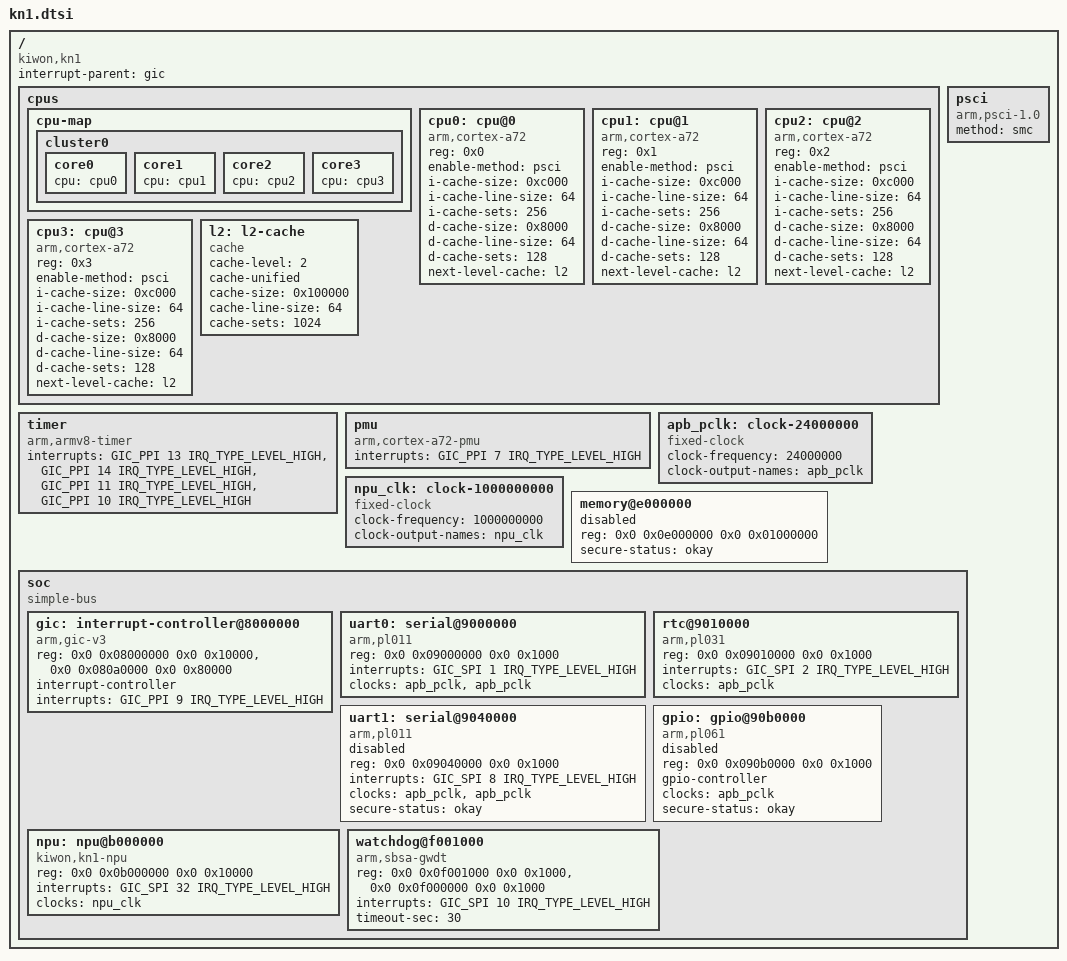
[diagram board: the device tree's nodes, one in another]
// SPDX-License-Identifier: GPL-2.0-or-later OR MIT
// SPDX-FileCopyrightText: 2026 Kiwon Kwon
/*
 * Kiwon kn1 SoC: 4x Cortex-A72, GICv3, PL011 UARTs, PL031 RTC,
 * SBSA generic watchdog, secure PL061 GPIO, secure on-chip RAM and the
 * kn1-npu.
 */

#include <dt-bindings/interrupt-controller/arm-gic.h>
#include <dt-bindings/interrupt-controller/irq.h>

/ {
	compatible = "kiwon,kn1";
	interrupt-parent = <&gic>;
	#address-cells = <2>;
	#size-cells = <2>;

	cpus {
		#address-cells = <1>;
		#size-cells = <0>;

		cpu-map {
			cluster0 {
				core0 {
					cpu = <&cpu0>;
				};
				core1 {
					cpu = <&cpu1>;
				};
				core2 {
					cpu = <&cpu2>;
				};
				core3 {
					cpu = <&cpu3>;
				};
			};
		};

		cpu0: cpu@0 {
			device_type = "cpu";
			compatible = "arm,cortex-a72";
			reg = <0x0>;
			enable-method = "psci";
			i-cache-size = <0xc000>;
			i-cache-line-size = <64>;
			i-cache-sets = <256>;
			d-cache-size = <0x8000>;
			d-cache-line-size = <64>;
			d-cache-sets = <128>;
			next-level-cache = <&l2>;
		};

		cpu1: cpu@1 {
			device_type = "cpu";
			compatible = "arm,cortex-a72";
			reg = <0x1>;
			enable-method = "psci";
			i-cache-size = <0xc000>;
			i-cache-line-size = <64>;
			i-cache-sets = <256>;
			d-cache-size = <0x8000>;
			d-cache-line-size = <64>;
			d-cache-sets = <128>;
			next-level-cache = <&l2>;
		};

		cpu2: cpu@2 {
			device_type = "cpu";
			compatible = "arm,cortex-a72";
			reg = <0x2>;
			enable-method = "psci";
			i-cache-size = <0xc000>;
			i-cache-line-size = <64>;
			i-cache-sets = <256>;
			d-cache-size = <0x8000>;
			d-cache-line-size = <64>;
			d-cache-sets = <128>;
			next-level-cache = <&l2>;
		};

		cpu3: cpu@3 {
			device_type = "cpu";
			compatible = "arm,cortex-a72";
			reg = <0x3>;
			enable-method = "psci";
			i-cache-size = <0xc000>;
			i-cache-line-size = <64>;
			i-cache-sets = <256>;
			d-cache-size = <0x8000>;
			d-cache-line-size = <64>;
			d-cache-sets = <128>;
			next-level-cache = <&l2>;
		};

		l2: l2-cache {
			compatible = "cache";
			cache-level = <2>;
			cache-unified;
			cache-size = <0x100000>;
			cache-line-size = <64>;
			cache-sets = <1024>;
		};
	};

	psci {
		compatible = "arm,psci-1.0";
		method = "smc";
	};

	timer {
		compatible = "arm,armv8-timer";
		interrupts = <GIC_PPI 13 IRQ_TYPE_LEVEL_HIGH>,
			     <GIC_PPI 14 IRQ_TYPE_LEVEL_HIGH>,
			     <GIC_PPI 11 IRQ_TYPE_LEVEL_HIGH>,
			     <GIC_PPI 10 IRQ_TYPE_LEVEL_HIGH>;
		interrupt-names = "sec-phys", "phys", "virt", "hyp-phys";
	};

	pmu {
		compatible = "arm,cortex-a72-pmu";
		interrupts = <GIC_PPI 7 IRQ_TYPE_LEVEL_HIGH>;
	};

	apb_pclk: clock-24000000 {
		compatible = "fixed-clock";
		#clock-cells = <0>;
		clock-frequency = <24000000>;
		clock-output-names = "apb_pclk";
	};

	/* The NPU does not model time; the rate only describes the clock */
	npu_clk: clock-1000000000 {
		compatible = "fixed-clock";
		#clock-cells = <0>;
		clock-frequency = <1000000000>;
		clock-output-names = "npu_clk";
	};

	/* On-chip RAM for the secure world only (TF-A BL2 and BL31) */
	memory@e000000 {
		device_type = "memory";
		reg = <0x0 0x0e000000 0x0 0x01000000>;
		status = "disabled";
		secure-status = "okay";
	};

	soc {
		compatible = "simple-bus";
		#address-cells = <2>;
		#size-cells = <2>;
		ranges;

		gic: interrupt-controller@8000000 {
			compatible = "arm,gic-v3";
			reg = <0x0 0x08000000 0x0 0x10000>,	/* GICD */
			      <0x0 0x080a0000 0x0 0x80000>;	/* GICR x4 */
			#interrupt-cells = <3>;
			interrupt-controller;
			interrupts = <GIC_PPI 9 IRQ_TYPE_LEVEL_HIGH>;
		};

		uart0: serial@9000000 {
			compatible = "arm,pl011", "arm,primecell";
			reg = <0x0 0x09000000 0x0 0x1000>;
			interrupts = <GIC_SPI 1 IRQ_TYPE_LEVEL_HIGH>;
			clocks = <&apb_pclk>, <&apb_pclk>;
			clock-names = "uartclk", "apb_pclk";
		};

		rtc@9010000 {
			compatible = "arm,pl031", "arm,primecell";
			reg = <0x0 0x09010000 0x0 0x1000>;
			interrupts = <GIC_SPI 2 IRQ_TYPE_LEVEL_HIGH>;
			clocks = <&apb_pclk>;
			clock-names = "apb_pclk";
		};

		uart1: serial@9040000 {
			compatible = "arm,pl011", "arm,primecell";
			reg = <0x0 0x09040000 0x0 0x1000>;
			interrupts = <GIC_SPI 8 IRQ_TYPE_LEVEL_HIGH>;
			clocks = <&apb_pclk>, <&apb_pclk>;
			clock-names = "uartclk", "apb_pclk";
			status = "disabled";
			secure-status = "okay";
		};

		gpio: gpio@90b0000 {
			compatible = "arm,pl061", "arm,primecell";
			reg = <0x0 0x090b0000 0x0 0x1000>;
			gpio-controller;
			#gpio-cells = <2>;
			clocks = <&apb_pclk>;
			clock-names = "apb_pclk";
			status = "disabled";
			secure-status = "okay";
		};

		npu: npu@b000000 {
			compatible = "kiwon,kn1-npu";
			reg = <0x0 0x0b000000 0x0 0x10000>;
			interrupts = <GIC_SPI 32 IRQ_TYPE_LEVEL_HIGH>;
			clocks = <&npu_clk>;
		};

		watchdog@f001000 {
			compatible = "arm,sbsa-gwdt";
			reg = <0x0 0x0f001000 0x0 0x1000>,	/* control */
			      <0x0 0x0f000000 0x0 0x1000>;	/* refresh */
			interrupts = <GIC_SPI 10 IRQ_TYPE_LEVEL_HIGH>;
			timeout-sec = <30>;
		};
	};
};
